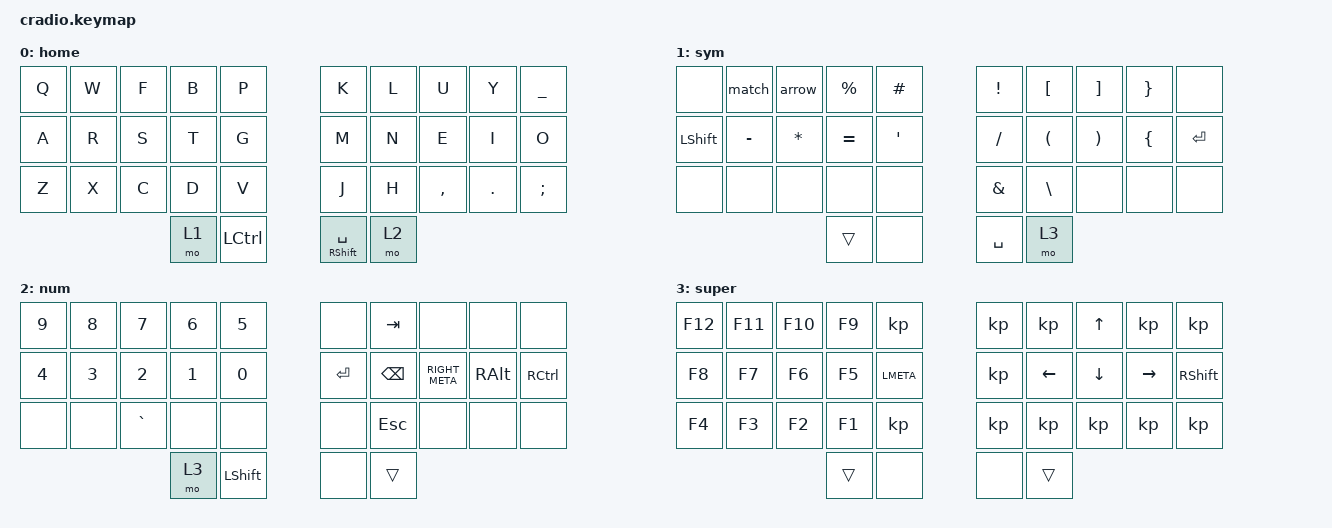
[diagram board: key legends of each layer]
// Copyright (c) 2022 The ZMK Contributors
// SPDX-License-Identifier: MIT

#include <behaviors.dtsi>
#include <dt-bindings/zmk/keys.h>

// Home row mods macro
//#define HRML(k1,k2,k3,k4) &ht LSHFT k1  &ht LALT k2  &ht LCTRL k3  &ht LGUI k4
//#define HRMR(k1,k2,k3,k4) &ht RGUI k1  &ht RCTRL k2  &ht RALT k3  &ht RSHFT k4

/ {
    behaviors {
        ht: hold_tap {
            compatible = "zmk,behavior-hold-tap";
            #binding-cells = <2>;
            flavor = "tap-preferred";
            tapping-term-ms = <220>;
            quick-tap-ms = <150>;
            require-prior-idle-ms = <100>;
            bindings = <&kp>, <&kp>;
        };
    };

    conditional_layers {
        compatible = "zmk,conditional-layers";

        tri_layer {
            if-layers = <0 0>;
            then-layer = <0>;
        };
    };

    macros {
        match: match {
            compatible = "zmk,behavior-macro";
            #binding-cells = <0>;
            bindings = <&kp EQUAL &kp GT>;
            label = "MATCH";
        };

        arrow: arrow {
            compatible = "zmk,behavior-macro";
            #binding-cells = <0>;
            bindings = <&kp MINUS &kp GT>;
            label = "ARROW";
        };
    };

    keymap {
        compatible = "zmk,keymap";

        home {
            bindings = <
&kp Q  &kp W  &kp F  &kp B  &kp P        &kp K            &kp L  &kp U      &kp Y       &kp UNDERSCORE
&kp A  &kp R  &kp S  &kp T  &kp G        &kp M            &kp N  &kp E      &kp I       &kp O
&kp Z  &kp X  &kp C  &kp D  &kp V        &kp J            &kp H  &kp COMMA  &kp PERIOD  &kp SEMICOLON
                     &mo 1  &kp LCTRL    &mt RSHFT SPACE  &mo 2
            >;
        };

        sym {
            bindings = <
&none      &match     &arrow        &kp PERCENT  &kp HASH    &kp EXCLAMATION  &kp LEFT_BRACKET      &kp RIGHT_BRACKET      &kp RIGHT_BRACE  &none
&kp LSHFT  &kp MINUS  &kp ASTERISK  &kp EQUAL    &kp SQT     &kp SLASH        &kp LEFT_PARENTHESIS  &kp RIGHT_PARENTHESIS  &kp LEFT_BRACE   &kp RET
&none      &none      &none         &none        &none       &kp AMPERSAND    &kp BACKSLASH         &none                  &none            &none
                                    &trans       &none       &kp SPACE        &mo 3
            >;
        };

        num {
            bindings = <
&kp N9        &kp N8        &kp N7        &kp NUMBER_6  &kp N5       &none    &kp TAB        &none           &none     &none
&kp NUMBER_4  &kp NUMBER_3  &kp NUMBER_2  &kp NUMBER_1  &kp N0       &kp RET  &kp BACKSPACE  &kp RIGHT_META  &kp RALT  &kp RCTRL
&none         &none         &kp GRAVE     &none         &none        &none    &kp ESCAPE     &none           &none     &none
                                          &mo 3         &kp LSHFT    &none    &trans
            >;
        };

        super {
            bindings = <
&kp F12  &kp F11  &kp F10  &kp F9  &kp          &kp    &kp       &kp UP_ARROW  &kp        &kp
&kp F8   &kp F7   &kp F6   &kp F5  &kp LMETA    &kp    &kp LEFT  &kp DOWN      &kp RIGHT  &kp RSHIFT
&kp F4   &kp F3   &kp F2   &kp F1  &kp          &kp    &kp       &kp           &kp        &kp
                           &trans  &none        &none  &trans
            >;
        };
    };
};
